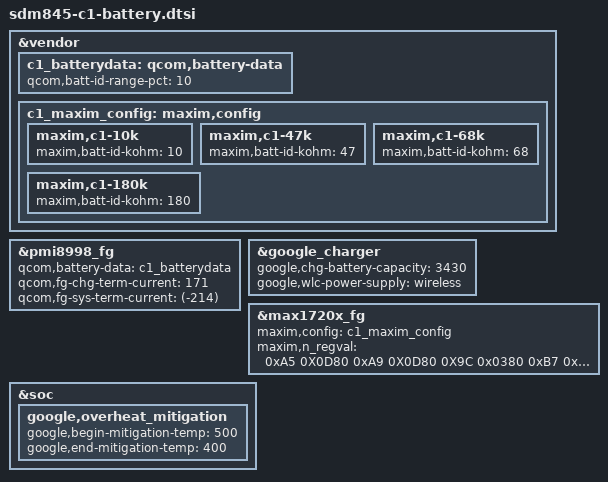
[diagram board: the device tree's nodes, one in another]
/* Copyright (c) 2017, The Linux Foundation. All rights reserved.
 *
 * This program is free software; you can redistribute it and/or modify
 * it under the terms of the GNU General Public License version 2 and
 * only version 2 as published by the Free Software Foundation.
 *
 * This program is distributed in the hope that it will be useful,
 * but WITHOUT ANY WARRANTY; without even the implied warranty of
 * MERCHANTABILITY or FITNESS FOR A PARTICULAR PURPOSE.  See the
 * GNU General Public License for more details.
 */

&vendor {
	c1_batterydata: qcom,battery-data {
		qcom,batt-id-range-pct = <10>;
		/*
		 * C1 regular
		 * --------------
		 * Desay using ATL cell - 10k
		 * Sunwoda using ATL cell - 47k
		 * Sunwoda using Coslight cell - 68k
		 * Desay using Coslight cell - 180k
		 */
		#include "batterydata-qcom-c1-10k.dtsi"
		#include "batterydata-qcom-c1-47k.dtsi"
		#include "batterydata-qcom-c1-68k.dtsi"
		#include "batterydata-qcom-c1-180k.dtsi"
	};
};

&pmi8998_fg {
	qcom,battery-data = <&c1_batterydata>;
	qcom,fg-chg-term-current = <171>;
	qcom,fg-sys-term-current = <(-214)>;
};

&google_charger {
	google,chg-battery-capacity = <3430>;
	google,wlc-power-supply = "wireless";
};

&vendor {
	c1_maxim_config: maxim,config {
		maxim,c1-10k {
			maxim,batt-id-kohm = <10>;
#include "batterydata-maxim-c1-10k.dtsi"
		};
		maxim,c1-47k {
			maxim,batt-id-kohm = <47>;
#include "batterydata-maxim-c1-47k.dtsi"
		};
		maxim,c1-68k {
			maxim,batt-id-kohm = <68>;
#include "batterydata-maxim-c1-68k.dtsi"
		};
		maxim,c1-180k {
			maxim,batt-id-kohm = <180>;
#include "batterydata-maxim-c1-180k.dtsi"
		};
	};
};

&max1720x_fg {
	maxim,config = <&c1_maxim_config>;
	maxim,n_regval =  /bits/ 16 <
	    0xA5 0X0D80 /* nFullCapNom = 3456 mAh */
	    0xA9 0X0D80 /* nFullCapRep = 3456 mAh */
	    0X9C 0x0380 /* nIChgTerm = 280 mA */
	    0xB7 0x2FC1	/* NConvgCfg: VoltLowOff = 620 mV */
	    0x9F 0x2602 /* nLearnCfg */
	    /* TAlrtEn required to route dSOC to ALRT1 pin */
	    0xB0 0x7217 /* nConfig: SS TS VS Tex Aen dSOCen TAlrtEn */
	    0xC0 0xFF00	/* nVAlrtTh: disabled */
	    0xC1 0x7F80 /* nTAlrtTh: disabled */
	    0xC2 0xFF00	/* nSAlrtTh: disabled */
	    0x9D 0x0EB4 /* nFilterCfg: Volt = 90 sec */
	    0xC6 0x5A05 /* nFullSOCThr = 90% */
	    0XB8 0xCDD0 /* nNVCfg0 */
	>;
};

&soc {
	google,overheat_mitigation {
		google,begin-mitigation-temp = <500>;
		google,end-mitigation-temp = <400>;
	};
};

